AUTOSAR XML (schema 4-0-3)
standard types defined: Boolean, UInt16
package /AUTOSAR_Platform/DataConstrs
  range DC_Boolean: raw 0..1
  range DC_UInt16: raw 0..65535
package /PATAC/MSM/ComponentTypes
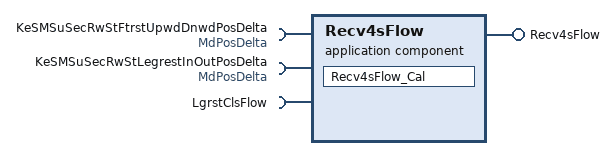
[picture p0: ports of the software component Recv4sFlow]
  application sw component type Recv4sFlow
    provide port Recv4sFlow: server-com-spec{operation=Recv4sFlow/Cal, queue-length=1}, provided-interface=Recv4sFlow
    require port KeSMSuSecRwStFtrstUpwdDnwdPosDelta: parameter-require-com-spec{init-value=150, parameter=Val}, required-interface=MdPosDelta
    require port KeSMSuSecRwStLegrestInOutPosDelta: parameter-require-com-spec{init-value=150, parameter=Val}, required-interface=MdPosDelta
    require port LgrstClsFlow: client-com-spec=LgrstClsFlow/Cal, required-interface=LgrstClsFlow
    behavior Recv4sFlow_InternalBehavior
      operation invoked event OIT_Recv4sFlow_Cal_Recv4sFlow_Cal: start-on-event=Recv4sFlow_Cal, operation=Recv4sFlow.Cal
      runnable Recv4sFlow_Cal
        parameter access PA_KeSMSuSecRwStFtrstUpwdDnwdPosDelta_Val: accessed-parameter=KeSMSuSecRwStFtrstUpwdDnwdPosDelta.Val
        parameter access PA_KeSMSuSecRwStLegrestInOutPosDelta_Val: accessed-parameter=KeSMSuSecRwStLegrestInOutPosDelta.Val
        sync call SC_LgrstClsFlow_Cal: operation=LgrstClsFlow.Cal, timeout=0
  swc implementation Recv4sFlow_Implementation: behavior=Recv4sFlow_InternalBehavior
    code-descriptors:
      code Default: artifact-descriptors=autosar-engineering-object={short-label=Default, category=SWSRC}
package /PATAC/MSM/ModeAdjust/CalPortInterface
  parameter interface MdPosDelta
    parameter data prototype Val: sw-calibration-access=READ-WRITE, type=UInt16
package /PATAC/MSM/ModeAdjust/PortInterface
  client server interface LgrstClsFlow
    operation Cal
      13 x arg, all with server-argument-impl-policy=USE-ARGUMENT-TYPE:
        LgrstUpwdDnwdPos: type=UInt16, direction=IN
        LgrstOtwdInwdPos: type=UInt16, direction=IN
        FtUpwdDnwdPos: type=UInt16, direction=IN
        CloseDnwdPos1: type=UInt16, direction=IN
        CloseDnwdPos2: type=UInt16, direction=IN
        CloseOtwdPos1: type=UInt16, direction=IN
        LgrstInwdStgDone: type=Boolean, direction=IN
        LgrstUpwdStgDone: type=Boolean, direction=IN
        FtrstStgDone: type=Boolean, direction=IN
        Failflg: type=Boolean, direction=OUT
        LgrstInwdOtwdEn: type=Boolean, direction=OUT
        LgrstUpwdDnwdEn: type=Boolean, direction=OUT
        FtrstEn: type=Boolean, direction=OUT
  client server interface Recv4sFlow
    operation Cal
      19 x arg, all with server-argument-impl-policy=USE-ARGUMENT-TYPE:
        LgrstUpwdDnwdPos: type=UInt16, direction=IN
        LgrstOtwdInwdPos: type=UInt16, direction=IN
        FtUpwdDnwdPos: type=UInt16, direction=IN
        CloseDnwdPos1: type=UInt16, direction=IN
        CloseDnwdPos2: type=UInt16, direction=IN
        CloseOtwdPos1: type=UInt16, direction=IN
        LgrstInwdStgDone: type=Boolean, direction=IN
        LgrstUpwdStgDone: type=Boolean, direction=IN
        FtrstStgDone: type=Boolean, direction=IN
        BkReclnStgDone: type=Boolean, direction=IN
        HdrstFwdBkwdStgDone: type=Boolean, direction=IN
        HdrstupwdDnwdStgDone: type=Boolean, direction=IN
        Failflg: type=Boolean, direction=OUT
        LgrstInwdOtwdEn: type=Boolean, direction=OUT
        LgrstUpwdDnwdEn: type=Boolean, direction=OUT
        FtrstEn: type=Boolean, direction=OUT
        BkReclnEn: type=Boolean, direction=OUT
        HdrstFrwdBkwdEn: type=Boolean, direction=OUT
        HdrstUpwdDnwdEn: type=Boolean, direction=OUT
